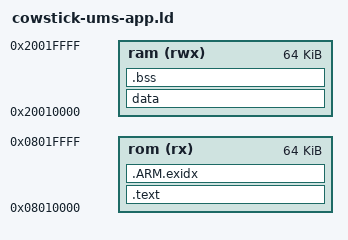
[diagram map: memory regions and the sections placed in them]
/**
 * @file cowstick-ums.ld
 * @brief Linker script for Cowstick-UMS
 *
 * @page License
 * Cowstick-UMS firmware is free software: you can redistribute it and/or
 * modify it under the terms of the GNU Lesser General Public License
 * version 3 as published by the Free Software Foundation. You should have
 * received a copy of the GNU Lesser General Public License along with this
 * program, see LICENSE.md file for more details.
 * This program is distributed WITHOUT ANY WARRANTY.
 */

OUTPUT_FORMAT("elf32-littlearm", "elf32-littlearm", "elf32-littlearm")
OUTPUT_ARCH(arm)
SEARCH_DIR(.)

/* Memory Spaces Definitions */
MEMORY
{
  rom      (rx)  : ORIGIN = 0x08010000, LENGTH = 0x00010000
  ram      (rwx) : ORIGIN = 0x20010000, LENGTH = 0x00010000
}

/* Section Definitions */
SECTIONS
{
    .text :
    {
        . = ALIGN(4);
        _sfixed = .;
        KEEP(*(.app_vector))
        *(.text .text.* .gnu.linkonce.t.*)
        *(.glue_7t) *(.glue_7)
        *(.rodata .rodata* .gnu.linkonce.r.*)
        *(.ARM.extab* .gnu.linkonce.armextab.*)

        /* Support C constructors, and C destructors in both user code
           and the C library. This also provides support for C++ code. */
        . = ALIGN(4);
        KEEP(*(.init))
        . = ALIGN(4);
        __preinit_array_start = .;
        KEEP (*(.preinit_array))
        __preinit_array_end = .;

        . = ALIGN(4);
        __init_array_start = .;
        KEEP (*(SORT(.init_array.*)))
        KEEP (*(.init_array))
        __init_array_end = .;

        . = ALIGN(4);
        KEEP (*crtbegin.o(.ctors))
        KEEP (*(EXCLUDE_FILE (*crtend.o) .ctors))
        KEEP (*(SORT(.ctors.*)))
        KEEP (*crtend.o(.ctors))

        . = ALIGN(4);
        KEEP(*(.fini))

        . = ALIGN(4);
        __fini_array_start = .;
        KEEP (*(.fini_array))
        KEEP (*(SORT(.fini_array.*)))
        __fini_array_end = .;

        KEEP (*crtbegin.o(.dtors))
        KEEP (*(EXCLUDE_FILE (*crtend.o) .dtors))
        KEEP (*(SORT(.dtors.*)))
        KEEP (*crtend.o(.dtors))

        . = ALIGN(4);
        _efixed = .;            /* End of text section */
    } > rom

    /* .ARM.exidx is sorted, so has to go in its own output section.  */
    PROVIDE_HIDDEN (__exidx_start = .);
    .ARM.exidx :
    {
      *(.ARM.exidx* .gnu.linkonce.armexidx.*)
    } > rom
    PROVIDE_HIDDEN (__exidx_end = .);

    . = ALIGN(4);
    _etext = .;

    data : AT (_etext)
    {
        . = ALIGN(4);
        __data_start__ = .;
        *(.ramfunc .ramfunc.*);
        *(.data .data.*);
        . = ALIGN(4);
        __data_end__ = .;
    } > ram

    /* .bss section which is used for uninitialized data */
    .bss (NOLOAD) :
    {
        . = ALIGN(4);
        _sbss = . ;
        _szero = .;
        *(.bss .bss.*)
        *(COMMON)
        . = ALIGN(4);
        _ebss = . ;
        _ezero = .;
    } > ram

    . = ALIGN(4);
    _end = . ;
}
